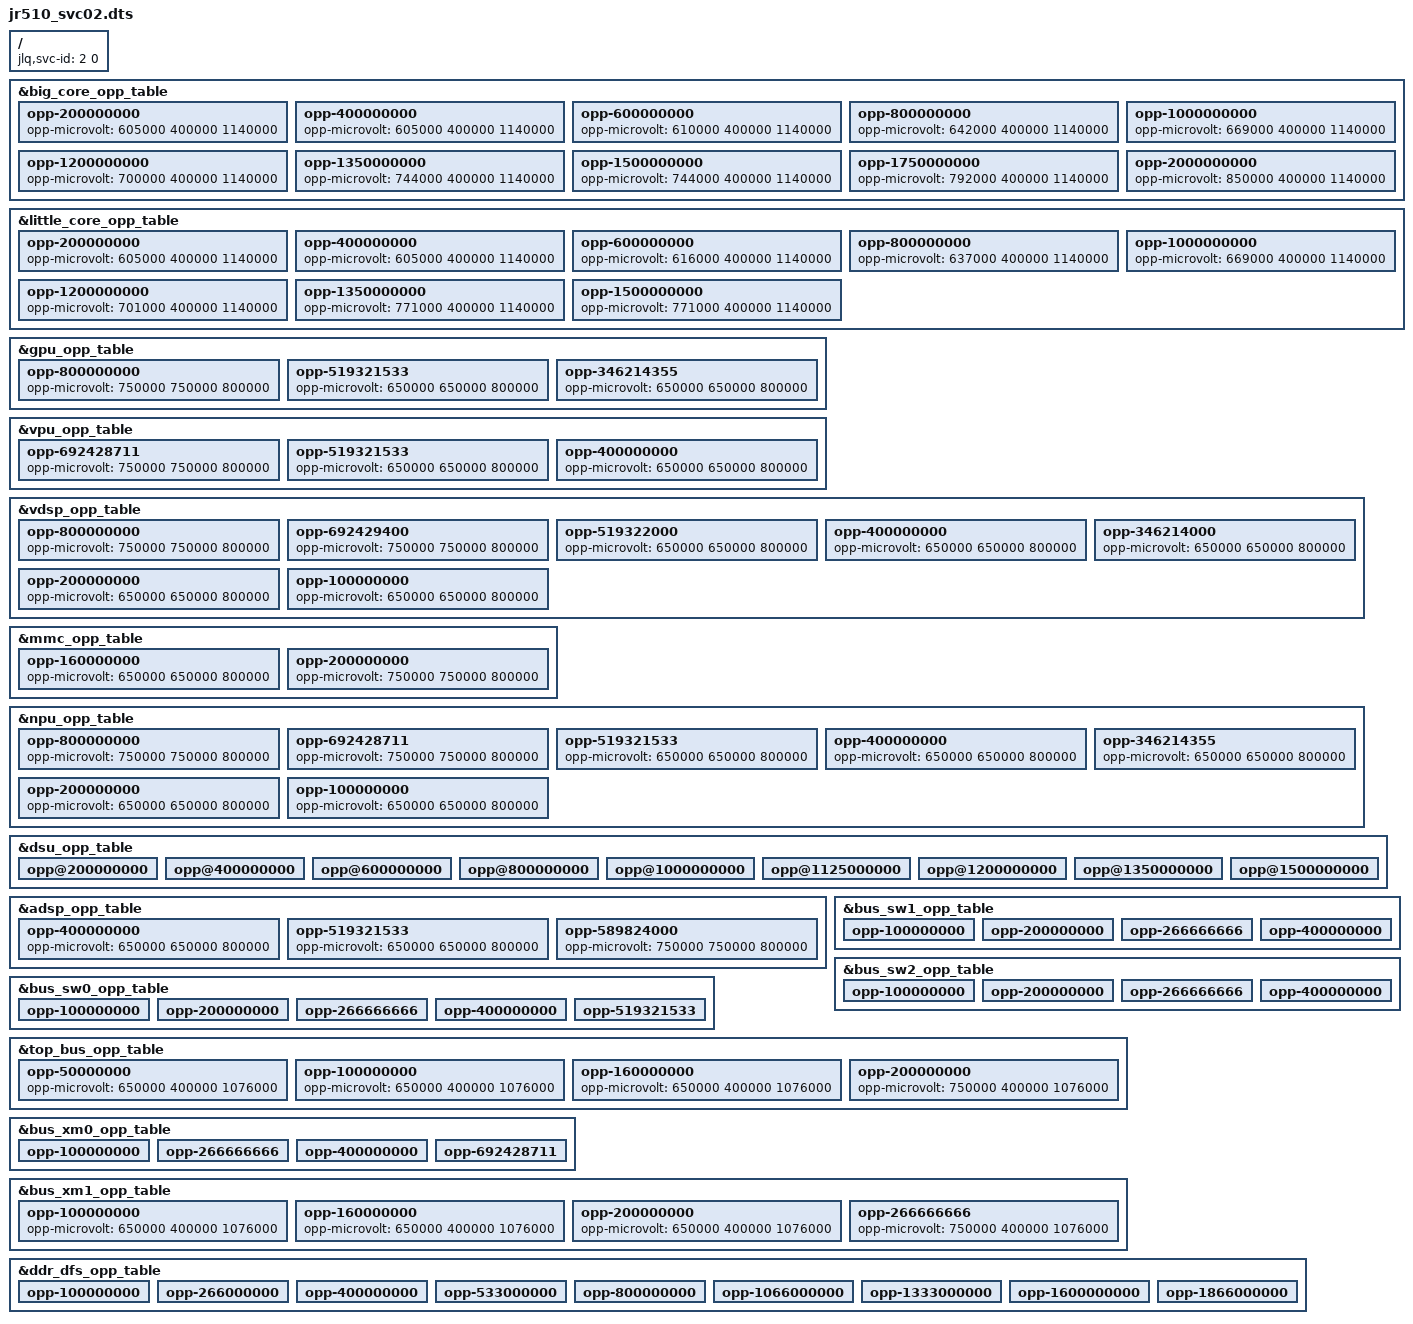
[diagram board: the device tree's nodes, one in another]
// SPDX-License-Identifier: GPL-2.0+
/dts-v1/;
/plugin/;
/ {
	jlq,svc-id = <2 0>;
};

&big_core_opp_table {
	opp-200000000 {
		opp-microvolt = <605000 400000 1140000>;
	};
	opp-400000000 {
		opp-microvolt = <605000 400000 1140000>;
	};
	opp-600000000 {
		opp-microvolt = <610000 400000 1140000>;
	};
	opp-800000000 {
		opp-microvolt = <642000 400000 1140000>;
	};
	opp-1000000000 {
		opp-microvolt = <669000 400000 1140000>;
	};
	opp-1200000000 {
		opp-microvolt = <700000 400000 1140000>;
	};
	opp-1350000000 {
		opp-microvolt = <744000 400000 1140000>;
	};
	opp-1500000000 {
		opp-microvolt = <744000 400000 1140000>;
	};

	opp-1750000000 {
		opp-microvolt = <792000 400000 1140000>;
	};
	opp-2000000000 {
		opp-microvolt = <850000 400000 1140000>;
	};
};

&little_core_opp_table {
	opp-200000000 {
		opp-microvolt = <605000 400000 1140000>;
	};
	opp-400000000 {
		opp-microvolt = <605000 400000 1140000>;
	};
	opp-600000000 {
		opp-microvolt = <616000 400000 1140000>;
	};
	opp-800000000 {
		opp-microvolt = <637000 400000 1140000>;
	};
	opp-1000000000 {
		opp-microvolt = <669000 400000 1140000>;
	};
	opp-1200000000 {
		opp-microvolt = <701000 400000 1140000>;
	};
	opp-1350000000 {
		opp-microvolt = <771000 400000 1140000>;
	};
	opp-1500000000 {
		opp-microvolt = <771000 400000 1140000>;
	};
};

&gpu_opp_table {
	opp-800000000 {
		opp-microvolt = <750000 750000 800000>;
	};
	/* opp-692428711 {
		opp-microvolt = <750000 750000 800000>;
	};
	*/
	opp-519321533 {
		opp-microvolt = <650000 650000 800000>;
	};
	/* opp-400000000 {
		opp-microvolt = <650000 650000 800000>;
	};
	*/
	opp-346214355 {
		opp-microvolt = <650000 650000 800000>;
	};
	/* opp-200000000 {
		opp-microvolt = <650000 650000 800000>;
	};
	opp-100000000 {
		opp-microvolt = <650000 650000 800000>;
	};
	*/
};

&vpu_opp_table {
	opp-692428711 {
		opp-microvolt = <750000 750000 800000>;
	};
	opp-519321533 {
		opp-microvolt = <650000 650000 800000>;
	};
	opp-400000000 {
		opp-microvolt = <650000 650000 800000>;
	};
};

&vdsp_opp_table {
	opp-800000000 {
		opp-microvolt = <750000 750000 800000>;
	};
	opp-692429400 {
		opp-microvolt = <750000 750000 800000>;
	};
	opp-519322000 {
		opp-microvolt = <650000 650000 800000>;
	};
	opp-400000000 {
		opp-microvolt = <650000 650000 800000>;
	};
	opp-346214000 {
		opp-microvolt = <650000 650000 800000>;
	};
	opp-200000000 {
		opp-microvolt = <650000 650000 800000>;
	};
	opp-100000000 {
		opp-microvolt = <650000 650000 800000>;
	};
};

&mmc_opp_table {
	opp-160000000 {
		opp-microvolt = <650000 650000 800000>;
	};
	opp-200000000 {
		opp-microvolt = <750000 750000 800000>;
	};
};

&npu_opp_table {
	opp-800000000 {
		opp-microvolt = <750000 750000 800000>;
	};
	opp-692428711 {
		opp-microvolt = <750000 750000 800000>;
	};
	opp-519321533 {
		opp-microvolt = <650000 650000 800000>;
	};
	opp-400000000 {
		opp-microvolt = <650000 650000 800000>;
	};
	opp-346214355 {
		opp-microvolt = <650000 650000 800000>;
	};
	opp-200000000 {
		opp-microvolt = <650000 650000 800000>;
	};
	opp-100000000 {
		opp-microvolt = <650000 650000 800000>;
	};
};

&dsu_opp_table {
	opp@200000000 {
		opp-microvolt = <610000 400000 1140000>,
				<530000 400000 1076000>,
				<650000 400000 1352000>;
	};
	opp@400000000 {
		opp-microvolt = <610000 400000 1140000>,
				<530000 400000 1076000>,
				<650000 400000 1352000>;
	};
	opp@600000000 {
		opp-microvolt = <621000 400000 1140000>,
				<541000 400000 1076000>,
				<650000 400000 1352000>;
	};
	opp@800000000 {
		opp-microvolt = <632000 400000 1140000>,
				<562000 400000 1076000>,
				<650000 400000 1352000>;
	};
	opp@1000000000 {
		opp-microvolt = <685000 400000 1140000>,
				<605000 400000 1076000>,
				<650000 400000 1352000>;
	};
	opp@1125000000 {
		opp-microvolt = <685000 400000 1140000>,
				<605000 400000 1076000>,
				<650000 400000 1352000>;
	};
	opp@1200000000 {
		opp-microvolt = <717000 400000 1140000>,
				<632000 400000 1076000>,
				<750000 400000 1352000>;
	};
	opp@1350000000 {
		opp-microvolt = <766000 400000 1140000>,
				<653000 400000 1076000>,
				<750000 400000 1352000>;
	};
	opp@1500000000 {
		opp-microvolt = <766000 400000 1140000>,
				<653000 400000 1076000>,
				<750000 400000 1352000>;
	};
};

&adsp_opp_table {
	opp-400000000 {
		opp-microvolt = <650000 650000 800000>;
	};
	opp-519321533 {
		opp-microvolt = <650000 650000 800000>;
	};
	opp-589824000 {
		opp-microvolt = <750000 750000 800000>;
	};
};

&bus_sw0_opp_table {
	opp-100000000 {
		opp-microvolt = <650000 400000 1076000>,
				<650000 400000 1352000>;
	};
	opp-200000000 {
		opp-microvolt = <650000 400000 1076000>,
				<650000 400000 1352000>;
	};
	opp-266666666 {
		opp-microvolt = <650000 400000 1076000>,
				<650000 400000 1352000>;
	};
	opp-400000000 {
		opp-microvolt = <650000 400000 1076000>,
				<650000 400000 1352000>;
	};
	opp-519321533 {
		opp-microvolt = <750000 400000 1076000>,
				<750000 400000 1352000>;
	};
};

&bus_sw1_opp_table {
	opp-100000000 {
		opp-microvolt = <650000 400000 1076000>,
				<650000 400000 1352000>;
	};
	opp-200000000 {
		opp-microvolt = <650000 400000 1076000>,
				<650000 400000 1352000>;
	};
	opp-266666666 {
		opp-microvolt = <650000 400000 1076000>,
				<650000 400000 1352000>;
	};
	opp-400000000 {
		opp-microvolt = <750000 400000 1076000>,
				<750000 400000 1352000>;
	};
};

&bus_sw2_opp_table {
	opp-100000000 {
		opp-microvolt = <650000 400000 1076000>,
				<650000 400000 1352000>;
	};
	opp-200000000 {
		opp-microvolt = <650000 400000 1076000>,
				<650000 400000 1352000>;
	};
	opp-266666666 {
		opp-microvolt = <650000 400000 1076000>,
				<650000 400000 1352000>;
	};
	opp-400000000 {
		opp-microvolt = <750000 400000 1076000>,
				<750000 400000 1352000>;
	};
};

&top_bus_opp_table {
	opp-50000000 {
		opp-microvolt = <650000 400000 1076000>;
	};
	opp-100000000 {
		opp-microvolt = <650000 400000 1076000>;
	};
	opp-160000000 {
		opp-microvolt = <650000 400000 1076000>;
	};
	opp-200000000 {
		opp-microvolt = <750000 400000 1076000>;
	};
};

&bus_xm0_opp_table {
	opp-100000000 {
		opp-microvolt = <650000 400000 1076000>,
				<650000 400000 1352000>;
	};
	opp-266666666 {
		opp-microvolt = <650000 400000 1076000>,
				<650000 400000 1352000>;
	};
	opp-400000000 {
		opp-microvolt = <650000 400000 1076000>,
				<650000 400000 1352000>;
	};
	opp-692428711 {
		opp-microvolt = <750000 400000 1076000>,
				<750000 400000 1352000>;
	};
};

&bus_xm1_opp_table {
	opp-100000000 {
		opp-microvolt = <650000 400000 1076000>;
	};
	opp-160000000 {
		opp-microvolt = <650000 400000 1076000>;
	};
	opp-200000000 {
		opp-microvolt = <650000 400000 1076000>;
	};
	opp-266666666 {
		opp-microvolt = <750000 400000 1076000>;
	};
};

&ddr_dfs_opp_table {
	opp-100000000 {
		opp-microvolt = <650000 400000 1076000>,
				<650000 400000 1352000>;
	};
	opp-266000000 {
		opp-microvolt = <650000 400000 1076000>,
				<650000 400000 1352000>;
	};
	opp-400000000 {
		opp-microvolt = <650000 400000 1076000>,
				<650000 400000 1352000>;
	};
	opp-533000000 {
		opp-microvolt = <650000 400000 1076000>,
				<650000 400000 1352000>;
	};
	opp-800000000 {
		opp-microvolt = <650000 400000 1076000>,
				<650000 400000 1352000>;
	};
	opp-1066000000 {
		opp-microvolt = <650000 400000 1076000>,
				<650000 400000 1352000>;
	};
	opp-1333000000 {
		opp-microvolt = <750000 400000 1076000>,
				<750000 400000 1352000>;
	};
	opp-1600000000 {
		opp-microvolt = <750000 400000 1076000>,
				<750000 400000 1352000>;
	};
	opp-1866000000 {
		opp-microvolt = <750000 400000 1076000>,
				<750000 400000 1352000>;
	};
};
